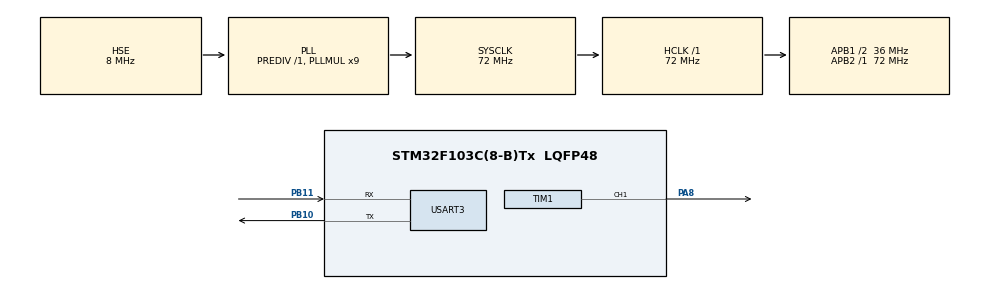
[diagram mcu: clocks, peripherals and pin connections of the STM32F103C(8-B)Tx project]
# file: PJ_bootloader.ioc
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Dma.Request0=TIM1_CH1
Dma.TIM1_CH1.0.Direction=DMA_MEMORY_TO_PERIPH
Dma.TIM1_CH1.0.Instance=DMA1_Channel2
Dma.TIM1_CH1.0.MemDataAlignment=DMA_MDATAALIGN_HALFWORD
Dma.TIM1_CH1.0.MemInc=DMA_MINC_ENABLE
Dma.TIM1_CH1.0.Mode=DMA_CIRCULAR
Dma.TIM1_CH1.0.PeriphDataAlignment=DMA_PDATAALIGN_HALFWORD
Dma.TIM1_CH1.0.PeriphInc=DMA_PINC_DISABLE
Dma.TIM1_CH1.0.Priority=DMA_PRIORITY_LOW
Mcu.Family=STM32F1
Mcu.Name=STM32F103C(8-B)Tx
Mcu.Package=LQFP48
NVIC.DMA1_Channel2_IRQn=true\:6\:0\:true\:false\:true\:false\:true
NVIC.PriorityGroup=NVIC_PRIORITYGROUP_4
NVIC.USART3_IRQn=true\:5\:0\:true\:false\:true\:true\:true
PA13.Mode=Serial_Wire
PA13.Signal=SYS_JTMS-SWDIO
PA14.Mode=Serial_Wire
PA14.Signal=SYS_JTCK-SWCLK
PA8.Signal=S_TIM1_CH1
PB10.Mode=Asynchronous
PB10.Signal=USART3_TX
PB11.Mode=Asynchronous
PB11.Signal=USART3_RX
PD0-OSC_IN.Mode=HSE-External-Oscillator
PD0-OSC_IN.Signal=RCC_OSC_IN
PD1-OSC_OUT.Mode=HSE-External-Oscillator
PD1-OSC_OUT.Signal=RCC_OSC_OUT
ProjectManager.HeapSize=0x200
ProjectManager.StackSize=0x400
ProjectManager.TargetToolchain=STM32CubeIDE
RCC.AHBFreq_Value=72000000
RCC.APB1CLKDivider=RCC_HCLK_DIV2
RCC.APB1Freq_Value=36000000
RCC.APB1TimFreq_Value=72000000
RCC.APB2Freq_Value=72000000
RCC.APB2TimFreq_Value=72000000
RCC.HCLKFreq_Value=72000000
RCC.PLLMUL=RCC_PLL_MUL9
RCC.PLLSourceVirtual=RCC_PLLSOURCE_HSE
RCC.SYSCLKFreq_VALUE=72000000
RCC.SYSCLKSource=RCC_SYSCLKSOURCE_PLLCLK
RCC.USBFreq_Value=72000000
SH.S_TIM1_CH1.0=TIM1_CH1,PWM Generation1 CH1
TIM1.Channel-PWM\ Generation1\ CH1=TIM_CHANNEL_1
TIM1.Period=90
USART3.VirtualMode=VM_ASYNC
board=custom

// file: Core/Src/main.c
/* USER CODE BEGIN Header */
/**
  ******************************************************************************
  * @file           : main.c
  * @brief          : Main program body
  ******************************************************************************
  * @attention
  *
  * <h2><center>&copy; Copyright (c) 2021 STMicroelectronics.
  * All rights reserved.</center></h2>
  *
  * This software component is licensed by ST under BSD 3-Clause license,
  * the "License"; You may not use this file except in compliance with the
  * License. You may obtain a copy of the License at:
  *                        opensource.org/licenses/BSD-3-Clause
  *
  ******************************************************************************
  */
/* USER CODE END Header */
#include "main.h"

/* USER CODE BEGIN Includes */
#include "bootloader.h"
#include "ws281x.h"
/* USER CODE END Includes */

TIM_HandleTypeDef htim1;
DMA_HandleTypeDef hdma_tim1_ch1;

UART_HandleTypeDef huart3;
volatile uint8_t  g_chunk_rdy = 0;
extern uint8_t UART3_IT_buffer[UPLOAD_FRAME_SIZE];
extern uint16_t UART3_byte_counter;

void SystemClock_Config(void);
static void MX_GPIO_Init(void);
static void MX_DMA_Init(void);
static void MX_TIM1_Init(void);
static void MX_USART3_UART_Init(void);

int main(void)
{
  /* USER CODE BEGIN 1 */
	//led animation vars
	uint8_t led_sens = 0;
	uint8_t led_idx =0;
	uint32_t led_tickstart = 0;

  /* USER CODE END 1 */

  /* MCU Configuration--------------------------------------------------------*/

  /* Reset of all peripherals, Initializes the Flash interface and the Systick. */
  HAL_Init();

  /* Configure the system clock */
  SystemClock_Config();

  /* Initialize all configured peripherals */
  MX_GPIO_Init();
  MX_DMA_Init();
  MX_TIM1_Init();
  MX_USART3_UART_Init();
  HAL_Delay(1);
  set_All_Leds_color(0,0,0);
  led_update();

  /* USER CODE BEGIN 2 */
  serial_send((uint8_t*)&"PJ bootloader start\n", strlen("PJ bootloader start\n"));
  bootloaderInit();

  /* USER CODE END 2 */

  /* Infinite loop */
  /* USER CODE BEGIN WHILE */
  while (1)
  {
	  if(g_chunk_rdy == 1) //firmware update process
	  {

		  if(write_big_packet_flash(UART3_IT_buffer) == 0)
		  {

			  writed_packet++;
			  memset(UART3_IT_buffer,0,UPLOAD_FRAME_SIZE);
			  UART3_byte_counter = 0; // we reset the buffer index

			  g_chunk_rdy = 0 ;
			  __HAL_UART_ENABLE_IT(&huart3,UART_IT_RXNE);// we set back uart  RX interupt for next packet
			  serial_send((uint8_t*)&"Flash: OK\n", strlen("Flash: OK\n")); // UPLOAD_PACKET_SIZE (256) bytes flashed
		  }
		  else
		  {
			  memset(UART3_IT_buffer,0,UPLOAD_FRAME_SIZE);
			  UART3_byte_counter = 0; // we reset the buffer index

			  g_chunk_rdy = 0 ;
			  __HAL_UART_ENABLE_IT(&huart3,UART_IT_RXNE);//we set back uart  RX interupt for next packet
			  serial_send((uint8_t*)&"Flashing Error!\n", strlen("Flashing Error!\n")); // indicate error while trying to flash the last UPLOAD_PACKET_SIZE (256) bytes

		  }
	  }

	  if(bootloaderMode == FlashMode && reboot_sig != 1)// if we are in firmware update mode
	  {
		  if((HAL_GetTick() - led_tickstart) > 200) // if 500 ms have ellapsed update led pattern
		  {
			  if(led_sens == 0) //left to right
			  {
				  set_All_Leds_color(0,0,0);
				  set_Led_color(led_idx,0,0,255);
				  led_idx++;
			  }
			  else //right to left
			  {
				  set_All_Leds_color(0,0,0);
				  set_Led_color(led_idx,0,0,255);
				  led_idx--;
			  }
			  led_update();
			  if(led_idx == (NUM_LEDS-1)) //change animation sens
			  {
				  led_sens = 1;
			  }
			  if(led_idx == 0)//change animation sens
			  {
				  led_sens = 0;
			  }

			  led_tickstart = HAL_GetTick();
		  }
	  }
	  else
	  {
		  reboot();
	  }

    /* USER CODE END WHILE */

  }
}

void SystemClock_Config(void)
{
  RCC_OscInitTypeDef RCC_OscInitStruct = {0};
  RCC_ClkInitTypeDef RCC_ClkInitStruct = {0};

  /** Initializes the RCC Oscillators according to the specified parameters
  * in the RCC_OscInitTypeDef structure.
  */
  RCC_OscInitStruct.OscillatorType = RCC_OSCILLATORTYPE_HSE;
  RCC_OscInitStruct.HSEState = RCC_HSE_ON;
  RCC_OscInitStruct.HSEPredivValue = RCC_HSE_PREDIV_DIV1;
  RCC_OscInitStruct.HSIState = RCC_HSI_ON;
  RCC_OscInitStruct.PLL.PLLState = RCC_PLL_ON;
  RCC_OscInitStruct.PLL.PLLSource = RCC_PLLSOURCE_HSE;
  RCC_OscInitStruct.PLL.PLLMUL = RCC_PLL_MUL9;
  if (HAL_RCC_OscConfig(&RCC_OscInitStruct) != HAL_OK)
  {
    Error_Handler();
  }
  /** Initializes the CPU, AHB and APB buses clocks
  */
  RCC_ClkInitStruct.ClockType = RCC_CLOCKTYPE_HCLK|RCC_CLOCKTYPE_SYSCLK
                              |RCC_CLOCKTYPE_PCLK1|RCC_CLOCKTYPE_PCLK2;
  RCC_ClkInitStruct.SYSCLKSource = RCC_SYSCLKSOURCE_PLLCLK;
  RCC_ClkInitStruct.AHBCLKDivider = RCC_SYSCLK_DIV1;
  RCC_ClkInitStruct.APB1CLKDivider = RCC_HCLK_DIV2;
  RCC_ClkInitStruct.APB2CLKDivider = RCC_HCLK_DIV1;

  if (HAL_RCC_ClockConfig(&RCC_ClkInitStruct, FLASH_LATENCY_2) != HAL_OK)
  {
    Error_Handler();
  }
}

static void MX_TIM1_Init(void)
{

  TIM_MasterConfigTypeDef sMasterConfig = {0};
  TIM_OC_InitTypeDef sConfigOC = {0};
  TIM_BreakDeadTimeConfigTypeDef sBreakDeadTimeConfig = {0};

  htim1.Instance = TIM1;
  htim1.Init.Prescaler = 0;
  htim1.Init.CounterMode = TIM_COUNTERMODE_UP;
  htim1.Init.Period = 89;
  htim1.Init.ClockDivision = TIM_CLOCKDIVISION_DIV1;
  htim1.Init.RepetitionCounter = 0;
  htim1.Init.AutoReloadPreload = TIM_AUTORELOAD_PRELOAD_DISABLE;
  if (HAL_TIM_PWM_Init(&htim1) != HAL_OK)
  {
    Error_Handler();
  }
  sMasterConfig.MasterOutputTrigger = TIM_TRGO_RESET;
  sMasterConfig.MasterSlaveMode = TIM_MASTERSLAVEMODE_DISABLE;
  if (HAL_TIMEx_MasterConfigSynchronization(&htim1, &sMasterConfig) != HAL_OK)
  {
    Error_Handler();
  }
  sConfigOC.OCMode = TIM_OCMODE_PWM1;
  sConfigOC.Pulse = 0;
  sConfigOC.OCPolarity = TIM_OCPOLARITY_HIGH;
  sConfigOC.OCNPolarity = TIM_OCNPOLARITY_HIGH;
  sConfigOC.OCFastMode = TIM_OCFAST_DISABLE;
  sConfigOC.OCIdleState = TIM_OCIDLESTATE_RESET;
  sConfigOC.OCNIdleState = TIM_OCNIDLESTATE_RESET;
  if (HAL_TIM_PWM_ConfigChannel(&htim1, &sConfigOC, TIM_CHANNEL_1) != HAL_OK)
  {
    Error_Handler();
  }
  sBreakDeadTimeConfig.OffStateRunMode = TIM_OSSR_DISABLE;
  sBreakDeadTimeConfig.OffStateIDLEMode = TIM_OSSI_DISABLE;
  sBreakDeadTimeConfig.LockLevel = TIM_LOCKLEVEL_OFF;
  sBreakDeadTimeConfig.DeadTime = 0;
  sBreakDeadTimeConfig.BreakState = TIM_BREAK_DISABLE;
  sBreakDeadTimeConfig.BreakPolarity = TIM_BREAKPOLARITY_HIGH;
  sBreakDeadTimeConfig.AutomaticOutput = TIM_AUTOMATICOUTPUT_DISABLE;
  if (HAL_TIMEx_ConfigBreakDeadTime(&htim1, &sBreakDeadTimeConfig) != HAL_OK)
  {
    Error_Handler();
  }
  HAL_TIM_MspPostInit(&htim1);

}

static void MX_USART3_UART_Init(void)
{

  huart3.Instance = USART3;
  huart3.Init.BaudRate = 9600;
  huart3.Init.WordLength = UART_WORDLENGTH_8B;
  huart3.Init.StopBits = UART_STOPBITS_1;
  huart3.Init.Parity = UART_PARITY_NONE;
  huart3.Init.Mode = UART_MODE_TX_RX;
  huart3.Init.HwFlowCtl = UART_HWCONTROL_NONE;
  huart3.Init.OverSampling = UART_OVERSAMPLING_16;
  if (HAL_UART_Init(&huart3) != HAL_OK)
  {
    Error_Handler();
  }
  /* USER CODE BEGIN USART3_Init 2 */
  __HAL_UART_ENABLE_IT(&huart3,UART_IT_RXNE);//enable uart  RX interupt here
  /* USER CODE END USART3_Init 2 */

}

static void MX_DMA_Init(void)
{

  /* DMA controller clock enable */
  __HAL_RCC_DMA1_CLK_ENABLE();

  /* DMA interrupt init */
  /* DMA1_Channel2_IRQn interrupt configuration */
  HAL_NVIC_SetPriority(DMA1_Channel2_IRQn, 6, 0);
  HAL_NVIC_EnableIRQ(DMA1_Channel2_IRQn);

}

static void MX_GPIO_Init(void)
{

  /* GPIO Ports Clock Enable */
  __HAL_RCC_GPIOD_CLK_ENABLE();
  __HAL_RCC_GPIOB_CLK_ENABLE();
  __HAL_RCC_GPIOA_CLK_ENABLE();
  __HAL_RCC_GPIOC_CLK_ENABLE();

}

void Error_Handler(void)
{
}

/************************ (C) COPYRIGHT STMicroelectronics *****END OF FILE****/
